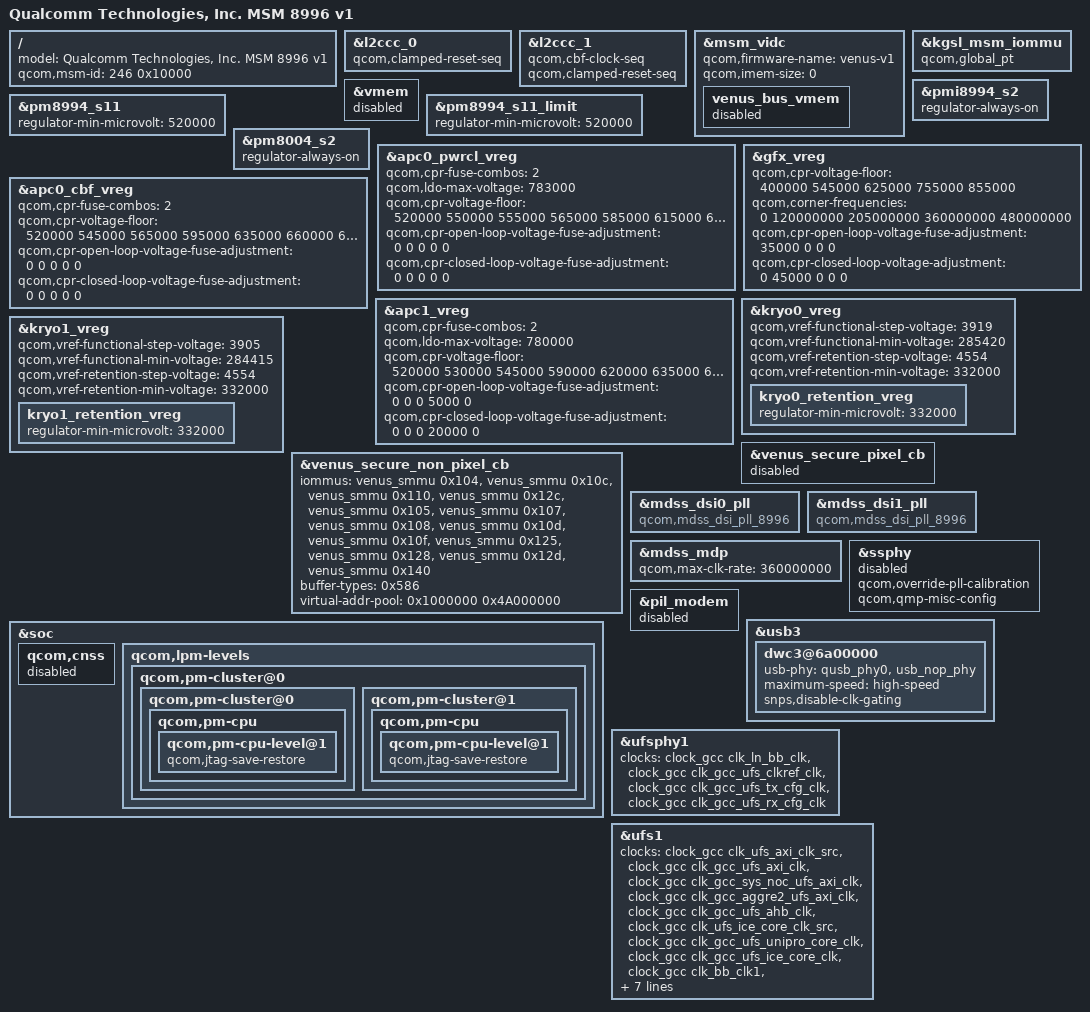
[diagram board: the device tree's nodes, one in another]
/* Copyright (c) 2014-2015, The Linux Foundation. All rights reserved.
 *
 * This program is free software; you can redistribute it and/or modify
 * it under the terms of the GNU General Public License version 2 and
 * only version 2 as published by the Free Software Foundation.
 *
 * This program is distributed in the hope that it will be useful,
 * but WITHOUT ANY WARRANTY; without even the implied warranty of
 * MERCHANTABILITY or FITNESS FOR A PARTICULAR PURPOSE.  See the
 * GNU General Public License for more details.
 */

/*
 * As a general rule, only version-specific property overrides should be placed
 * inside this file. Common device definitions should be placed inside the
 * msm8996.dtsi file.
 */

#include "msm8996.dtsi"
#include "msm-arm-smmu-8996v1.dtsi"
#include "msm8996-coresight-v1.dtsi"

/ {
	model = "Qualcomm Technologies, Inc. MSM 8996 v1";
	qcom,msm-id = <246 0x10000>;
};

&l2ccc_0 {
	qcom,clamped-reset-seq;
};

&l2ccc_1 {
	qcom,cbf-clock-seq;
	qcom,clamped-reset-seq;
};

&msm_vidc {
	qcom,firmware-name = "venus-v1";
	qcom,imem-size = <0>;

	/* Buses */
	venus_bus_vmem {
		status = "disabled";
	};

};

&kgsl_msm_iommu {
	 qcom,global_pt;
};

&vmem {
	status = "disabled";
};

&pm8994_s11 {
	regulator-min-microvolt = <520000>;
};

&pm8994_s11_limit {
	regulator-min-microvolt = <520000>;
};

/* Ensure that both possible VDD_GFX supplies cannot be disabled. */
&pmi8994_s2 {
	regulator-always-on;
};

&pm8004_s2 {
	regulator-always-on;
};

&apc0_pwrcl_vreg {
	qcom,cpr-fuse-combos = <2>;
	qcom,ldo-max-voltage = <783000>;
	qcom,cpr-voltage-floor =
		<520000 550000 555000 565000 585000 615000 635000 655000 690000
		 720000 740000 750000 760000 770000 780000 790000 815000 840000
		 850000>;
	/delete-property/ qcom,cpr-floor-to-ceiling-max-range;
	qcom,cpr-open-loop-voltage-fuse-adjustment =   <0 0 0 0 0>;
	qcom,cpr-closed-loop-voltage-fuse-adjustment = <0 0 0 0 0>;
};

&apc0_cbf_vreg {
	qcom,cpr-fuse-combos = <2>;
	qcom,cpr-voltage-floor =
		<520000 545000 565000 595000 635000 660000 690000 730000 750000
		 850000>;
	/delete-property/ qcom,cpr-floor-to-ceiling-max-range;
	qcom,cpr-open-loop-voltage-fuse-adjustment =   <0 0 0 0 0>;
	qcom,cpr-closed-loop-voltage-fuse-adjustment = <0 0 0 0 0>;
};

&apc1_vreg {
	qcom,cpr-fuse-combos = <2>;
	qcom,ldo-max-voltage = <780000>;
	qcom,cpr-voltage-floor =
		<520000 530000 545000 590000 620000 635000 660000 685000 700000
		 730000 740000 750000 765000 790000 805000 815000 830000
		 850000>;
	/delete-property/ qcom,cpr-floor-to-ceiling-max-range;
	qcom,cpr-open-loop-voltage-fuse-adjustment =   <0 0 0 5000 0>;
	qcom,cpr-closed-loop-voltage-fuse-adjustment = <0 0 0 20000 0>;
};

&gfx_vreg {
	qcom,cpr-voltage-floor = <400000 545000 625000 755000 855000>;
	/delete-property/ qcom,cpr-floor-to-ceiling-max-range;
	qcom,corner-frequencies = <0 120000000 205000000 360000000 480000000>;
	qcom,cpr-open-loop-voltage-fuse-adjustment = <35000 0 0 0>;
	qcom,cpr-closed-loop-voltage-adjustment = <0 45000 0 0 0>;
};

&kryo0_vreg {
	qcom,vref-functional-step-voltage = <3919>;
	qcom,vref-functional-min-voltage = <285420>;
	qcom,vref-retention-step-voltage = <4554>;
	qcom,vref-retention-min-voltage = <332000>;

	kryo0_retention_vreg {
		regulator-min-microvolt = <332000>;
	};
};

&kryo1_vreg {
	qcom,vref-functional-step-voltage = <3905>;
	qcom,vref-functional-min-voltage = <284415>;
	qcom,vref-retention-step-voltage = <4554>;
	qcom,vref-retention-min-voltage = <332000>;

	kryo1_retention_vreg {
		regulator-min-microvolt = <332000>;
	};
};

&venus_secure_pixel_cb {
	status = "disabled";
};

&venus_secure_non_pixel_cb {
	iommus = <&venus_smmu 0x104>,
	       <&venus_smmu 0x10c>,
	       <&venus_smmu 0x110>,
	       <&venus_smmu 0x12c>,
	       <&venus_smmu 0x105>,
	       <&venus_smmu 0x107>,
	       <&venus_smmu 0x108>,
	       <&venus_smmu 0x10d>,
	       <&venus_smmu 0x10f>,
	       <&venus_smmu 0x125>,
	       <&venus_smmu 0x128>,
	       <&venus_smmu 0x12d>,
	       <&venus_smmu 0x140>;
	buffer-types = <0x586>;
	virtual-addr-pool = <0x1000000 0x4A000000>;
};

&soc {
	qcom,cnss {
		status = "disabled";
	};

	qcom,lpm-levels {
		qcom,pm-cluster@0 {
			qcom,pm-cluster@0{
				qcom,pm-cpu {
					qcom,pm-cpu-level@1 { /* C4 */
						qcom,jtag-save-restore;
					};
				};
			};

			qcom,pm-cluster@1{
				qcom,pm-cpu {
					qcom,pm-cpu-level@1 { /* C4 */
						qcom,jtag-save-restore;
					};
				};
			};
		};
	};
};

&mdss_dsi0_pll {
	compatible = "qcom,mdss_dsi_pll_8996";
};

&mdss_dsi1_pll {
	compatible = "qcom,mdss_dsi_pll_8996";
};

&mdss_mdp {
	qcom,max-clk-rate = <360000000>;
};

&ssphy {
	qcom,override-pll-calibration;
	qcom,qmp-misc-config;
	status = "disabled";
};

&pil_modem {
	status = "disabled";
};

&usb3 {
	dwc3@6a00000 {
		usb-phy = <&qusb_phy0>, <&usb_nop_phy>;
		maximum-speed = "high-speed";
		snps,disable-clk-gating;
	};
};

&ufsphy1 {
	clock-names = "ref_clk_src",
		"ref_clk",
		"tx_iface_clk",
		"rx_iface_clk";
	clocks = <&clock_gcc clk_ln_bb_clk>,
		<&clock_gcc clk_gcc_ufs_clkref_clk>,
		<&clock_gcc clk_gcc_ufs_tx_cfg_clk>,
		<&clock_gcc clk_gcc_ufs_rx_cfg_clk>;
};

&ufs1 {
	clock-names =
		"core_clk_src",
		"core_clk",
		"bus_clk",
		"bus_aggr_clk",
		"iface_clk",
		"core_clk_unipro_src",
		"core_clk_unipro",
		"core_clk_ice",
		"ref_clk",
		"tx_lane0_sync_clk",
		"rx_lane0_sync_clk",
		"sys_clk_core_clk",
		"tx_symbol_clk_core_clk";
	clocks =
		<&clock_gcc clk_ufs_axi_clk_src>,
		<&clock_gcc clk_gcc_ufs_axi_clk>,
		<&clock_gcc clk_gcc_sys_noc_ufs_axi_clk>,
		<&clock_gcc clk_gcc_aggre2_ufs_axi_clk>,
		<&clock_gcc clk_gcc_ufs_ahb_clk>,
		<&clock_gcc clk_ufs_ice_core_clk_src>,
		<&clock_gcc clk_gcc_ufs_unipro_core_clk>,
		<&clock_gcc clk_gcc_ufs_ice_core_clk>,
		<&clock_gcc clk_bb_clk1>,
		<&clock_gcc clk_gcc_ufs_tx_symbol_0_clk>,
		<&clock_gcc clk_gcc_ufs_rx_symbol_0_clk>,
		<&clock_gcc clk_gcc_ufs_sys_clk_core_clk>,
		<&clock_gcc clk_gcc_ufs_tx_symbol_clk_core_clk>;
	freq-table-hz =
		<100000000 200000000>,
		<0 0>,
		<0 0>,
		<0 0>,
		<0 0>,
		<150000000 300000000>,
		<0 0>,
		<0 0>,
		<0 0>,
		<0 0>,
		<0 0>,
		<0 0>,
		<0 0>;
};
